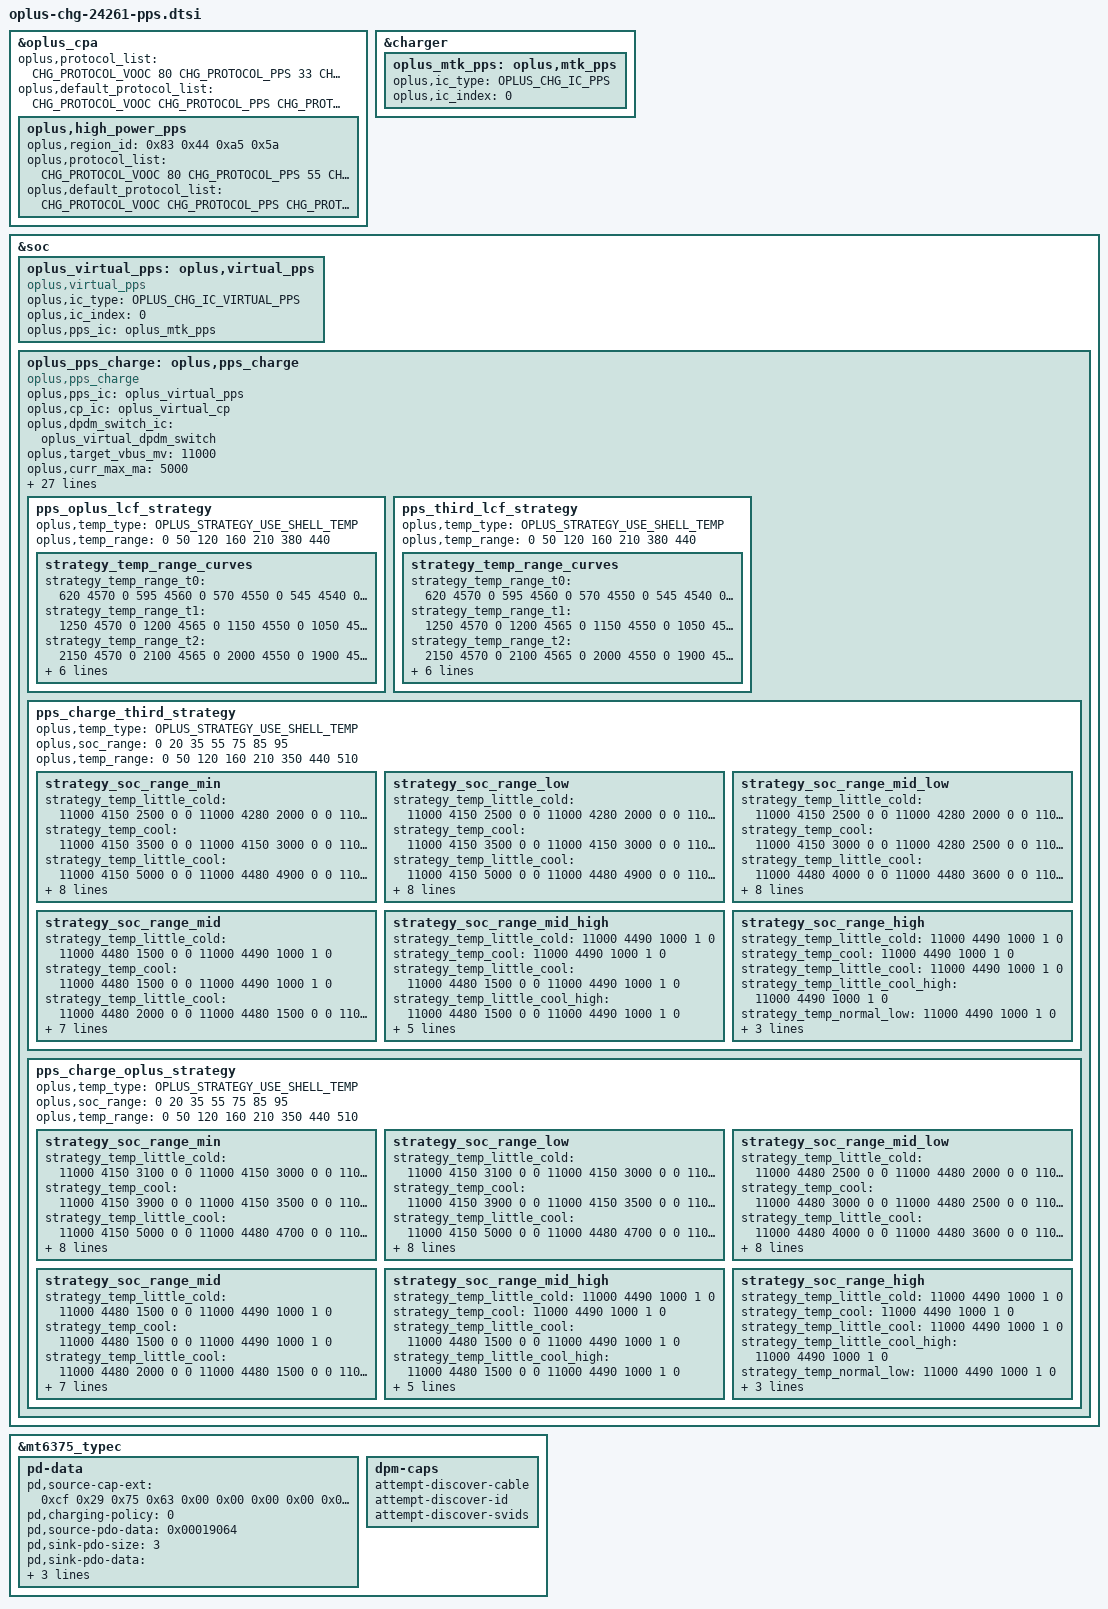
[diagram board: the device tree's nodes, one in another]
//ifdef OPLUS_FEATURE_CHG_BASIC
&oplus_cpa {
	oplus,protocol_list = <CHG_PROTOCOL_VOOC 80
			       CHG_PROTOCOL_PPS 33
			       CHG_PROTOCOL_PD 18
			       CHG_PROTOCOL_QC 18>;
	oplus,default_protocol_list = <CHG_PROTOCOL_VOOC
				       CHG_PROTOCOL_PPS
				       CHG_PROTOCOL_PD>;
	oplus,high_power_pps {
		oplus,region_id = /bits/ 8 <0x83 0x44 0xa5 0x5a>;
		oplus,protocol_list = <CHG_PROTOCOL_VOOC 80
				       CHG_PROTOCOL_PPS 55
				       CHG_PROTOCOL_PD 18
				       CHG_PROTOCOL_QC 18>;
		oplus,default_protocol_list = <CHG_PROTOCOL_VOOC
					       CHG_PROTOCOL_PPS
					       CHG_PROTOCOL_PD>;
	};
};

&charger {
	oplus_mtk_pps: oplus,mtk_pps {
		oplus,ic_type = <OPLUS_CHG_IC_PPS>;
		oplus,ic_index = <0>;
	};
};
&soc {
	oplus_virtual_pps: oplus,virtual_pps {
		compatible = "oplus,virtual_pps";

		oplus,ic_type = <OPLUS_CHG_IC_VIRTUAL_PPS>;
		oplus,ic_index = <0>;
		oplus,pps_ic = <&oplus_mtk_pps>;
	};
	oplus_pps_charge: oplus,pps_charge {
		compatible = "oplus,pps_charge";
		oplus,pps_ic = <&oplus_virtual_pps>;
		oplus,cp_ic = <&oplus_virtual_cp>;
		oplus,dpdm_switch_ic = <&oplus_virtual_dpdm_switch>;

		oplus,target_vbus_mv = <11000>;
		oplus,curr_max_ma = <5000>;

		oplus,pps_warm_allow_vol = <4000>;
		oplus,pps_warm_allow_soc = <50>;
		oplus,pps_strategy_normal_current = <5000>;
		oplus,pps_over_high_or_low_current = <3000>;
		oplus,pps_timeout_third = <10800>;
		oplus,pps_timeout_oplus = <10800>;
		oplus,pps_ibat_over_third = <12000>;
		oplus,pps_ibat_over_oplus = <12000>;
		oplus,pps_full_cool_sw_vbat = <4490>;
		oplus,pps_full_normal_sw_vbat = <4490>;
		oplus,pps_full_normal_hw_vbat = <4500>;
		oplus,pps_full_ffc_vbat = <4500>;
		oplus,pps_full_warm_vbat = <4130>;
		oplus,pps_full_cool_sw_vbat_third = <4490>;
		oplus,pps_full_normal_sw_vbat_third= <4490>;
		oplus,pps_full_normal_hw_vbat_third = <4500>;
		oplus,pps_current_change_timeout = <100>;
		oplus,curve_strategy_name = "pps_ufcs_curve_v2";
		oplus,pps_strategy_batt_high_temp = <410 420 430 400 410 420>;
		oplus,pps_strategy_high_current = <5000 4000 3000 5000 4000 3000>;
		oplus,pps_little_cool_high_temp = <210>;
		oplus,pps_charge_strategy_soc = <0 20 35 55 75 85 95>;
		oplus,pps_charge_strategy_temp = <0 50 120 160 350 440 510>;

		pps_oplus_lcf_strategy {
			oplus,temp_type = <OPLUS_STRATEGY_USE_SHELL_TEMP>;
			oplus,temp_range = <0 50 120 160 210 380 440>;

			strategy_temp_range_curves {
				strategy_temp_range_t0 =	<620 4570 0
								 595 4560 0
								 570 4550 0
								 545 4540 0
								 520 4530 1>;
				strategy_temp_range_t1 =	<1250 4570 0
								 1200 4565 0
								 1150 4550 0
								 1050 4540 0
								 950 4530 1>;
				strategy_temp_range_t2 =	<2150 4570 0
								 2100 4565 0
								 2000 4550 0
								 1900 4540 0
								 1750 4530 1>;
				strategy_temp_range_t3 =	<3400 4570 0
								 3350 4565 0
								 3250 4550 0
								 3150 4540 0
								 3000 4530 1>;
				strategy_temp_range_t4 =	<3400 4570 0
								 3350 4565 0
								 3250 4550 0
								 3150 4540 0
								 3000 4530 1>;
				strategy_temp_range_t5 =	<4300 4570 0
								 4250 4565 0
								 4150 4550 0
								 4050 4540 0
								 3900 4530 1>;
			};
		};

		pps_third_lcf_strategy {
			oplus,temp_type = <OPLUS_STRATEGY_USE_SHELL_TEMP>;
			oplus,temp_range = <0 50 120 160 210 380 440>;

			strategy_temp_range_curves {
				strategy_temp_range_t0 =	<620 4570 0
								 595 4560 0
								 570 4550 0
								 545 4540 0
								 520 4530 1>;
				strategy_temp_range_t1 =	<1250 4570 0
								 1200 4565 0
								 1150 4550 0
								 1050 4540 0
								 950 4530 1>;
				strategy_temp_range_t2 =	<2150 4570 0
								 2100 4565 0
								 2000 4550 0
								 1900 4540 0
								 1750 4530 1>;
				strategy_temp_range_t3 =	<3400 4570 0
								 3350 4565 0
								 3250 4550 0
								 3150 4540 0
								 3000 4530 1>;
				strategy_temp_range_t4 =	<3400 4570 0
								 3350 4565 0
								 3250 4550 0
								 3150 4540 0
								 3000 4530 1>;
				strategy_temp_range_t5 =	<4300 4570 0
								 4250 4565 0
								 4150 4550 0
								 4050 4540 0
								 3900 4530 1>;
			};
		};

		pps_charge_third_strategy {
			oplus,temp_type = <OPLUS_STRATEGY_USE_SHELL_TEMP>;
			oplus,soc_range = <0 20 35 55 75 85 95>;
			oplus,temp_range = <0 50 120 160 210 350 440 510>;

			strategy_soc_range_min {
				strategy_temp_little_cold =	<11000 4150 2500 0 0
								11000 4280 2000 0 0
								11000 4480 1500 0 0
								11000 4490 1000 1 0>;
				strategy_temp_cool =		<11000 4150 3500 0 0
								11000 4150 3000 0 0
								11000 4280 2500 0 0
								11000 4480 2000 0 0
								11000 4480 1500 0 0
								11000 4490 1000 1 0>;
				strategy_temp_little_cool =	<11000 4150 5000 0 0
								11000 4480 4900 0 0
								11000 4480 4000 0 0
								11000 4480 3600 0 0
								11000 4480 3500 0 0
								11000 4480 3000 0 0
								11000 4480 2500 0 0
								11000 4480 2000 0 0
								11000 4480 1500 0 0
								11000 4490 1000 1 0>;
				strategy_temp_little_cool_high =	<11000 4280 5000 0 0
								11000 4480 4900 0 0
								11000 4480 4000 0 0
								11000 4480 3600 0 0
								11000 4480 3500 0 0
								11000 4480 3000 0 0
								11000 4480 2500 0 0
								11000 4480 2000 0 0
								11000 4480 1500 0 0
								11000 4490 1000 1 0>;
				strategy_temp_normal_low =	<11000 4280 5000 0 0
								11000 4480 4900 0 0
								11000 4480 4000 0 0
								11000 4480 3600 0 0
								11000 4480 3500 0 0
								11000 4480 3000 0 0
								11000 4480 2500 0 0
								11000 4480 2000 0 0
								11000 4480 1500 0 0
								11000 4490 1000 1 0>;
				strategy_temp_normal_high =	<11000 4280 5000 0 0
								11000 4460 4900 0 0
								11000 4460 4000 0 0
								11000 4460 3600 0 0
								11000 4460 3500 0 0
								11000 4460 3000 0 0
								11000 4460 2500 0 0
								11000 4460 2000 0 0
								11000 4460 1500 0 0
								11000 4470 1000 1 0>;
				strategy_temp_warm =		<11000 4120 1500 0 0
								11000 4130 1000 1 0>;
			};
			strategy_soc_range_low {
				strategy_temp_little_cold =	<11000 4150 2500 0 0
								11000 4280 2000 0 0
								11000 4480 1500 0 0
								11000 4490 1000 1 0>;
				strategy_temp_cool =		<11000 4150 3500 0 0
								11000 4150 3000 0 0
								11000 4280 2500 0 0
								11000 4480 2000 0 0
								11000 4480 1500 0 0
								11000 4490 1000 1 0>;
				strategy_temp_little_cool =	<11000 4150 5000 0 0
								11000 4480 4900 0 0
								11000 4480 4000 0 0
								11000 4480 3600 0 0
								11000 4480 3500 0 0
								11000 4480 3000 0 0
								11000 4480 2500 0 0
								11000 4480 2000 0 0
								11000 4480 1500 0 0
								11000 4490 1000 1 0>;
				strategy_temp_little_cool_high =	<11000 4280 5000 0 0
								11000 4480 4900 0 0
								11000 4480 4000 0 0
								11000 4480 3600 0 0
								11000 4480 3500 0 0
								11000 4480 3000 0 0
								11000 4480 2500 0 0
								11000 4480 2000 0 0
								11000 4480 1500 0 0
								11000 4490 1000 1 0>;
				strategy_temp_normal_low =	<11000 4280 5000 0 0
								11000 4480 4900 0 0
								11000 4480 4000 0 0
								11000 4480 3600 0 0
								11000 4480 3500 0 0
								11000 4480 3000 0 0
								11000 4480 2500 0 0
								11000 4480 2000 0 0
								11000 4480 1500 0 0
								11000 4490 1000 1 0>;
				strategy_temp_normal_high =	<11000 4280 5000 0 0
								11000 4460 4900 0 0
								11000 4460 4000 0 0
								11000 4460 3600 0 0
								11000 4460 3500 0 0
								11000 4460 3000 0 0
								11000 4460 2500 0 0
								11000 4460 2000 0 0
								11000 4460 1500 0 0
								11000 4470 1000 1 0>;
				strategy_temp_warm =		<11000 4120 1500 0 0
								11000 4130 1000 1 0>;
			};
			strategy_soc_range_mid_low {
				strategy_temp_little_cold =	<11000 4150 2500 0 0
								11000 4280 2000 0 0
								11000 4480 1500 0 0
								11000 4490 1000 1 0>;
				strategy_temp_cool =		<11000 4150 3000 0 0
								11000 4280 2500 0 0
								11000 4480 2000 0 0
								11000 4480 1500 0 0
								11000 4490 1000 1 0>;
				strategy_temp_little_cool =	<11000 4480 4000 0 0
								11000 4480 3600 0 0
								11000 4480 3500 0 0
								11000 4480 3000 0 0
								11000 4480 2500 0 0
								11000 4480 2000 0 0
								11000 4480 1500 0 0
								11000 4490 1000 1 0>;
				strategy_temp_little_cool_high =	<11000 4480 4000 0 0
								11000 4480 3600 0 0
								11000 4480 3500 0 0
								11000 4480 3000 0 0
								11000 4480 2500 0 0
								11000 4480 2000 0 0
								11000 4480 1500 0 0
								11000 4490 1000 1 0>;
				strategy_temp_normal_low =	<11000 4280 5000 0 0
								11000 4480 4900 0 0
								11000 4480 4000 0 0
								11000 4480 3600 0 0
								11000 4480 3500 0 0
								11000 4480 3000 0 0
								11000 4480 2500 0 0
								11000 4480 2000 0 0
								11000 4480 1500 0 0
								11000 4490 1000 1 0>;
				strategy_temp_normal_high =	<11000 4280 5000 0 0
								11000 4460 4900 0 0
								11000 4460 4000 0 0
								11000 4460 3600 0 0
								11000 4460 3500 0 0
								11000 4460 3000 0 0
								11000 4460 2500 0 0
								11000 4460 2000 0 0
								11000 4460 1500 0 0
								11000 4470 1000 1 0>;
				strategy_temp_warm =		<11000 4120 1500 0 0
								11000 4130 1000 1 0>;
			};
			strategy_soc_range_mid {
				strategy_temp_little_cold =	<11000 4480 1500 0 0
								11000 4490 1000 1 0>;
				strategy_temp_cool =		<11000 4480 1500 0 0
								11000 4490 1000 1 0>;
				strategy_temp_little_cool =	<11000 4480 2000 0 0
								11000 4480 1500 0 0
								11000 4490 1000 1 0>;
				strategy_temp_little_cool_high =	<11000 4480 2000 0 0
								11000 4480 1500 0 0
								11000 4490 1000 1 0>;
				strategy_temp_normal_low =	<11000 4480 2500 0 0
								11000 4480 2000 0 0
								11000 4480 1500 0 0
								11000 4490 1000 1 0>;
				strategy_temp_normal_high =	<11000 4460 3000 0 0
								11000 4460 2500 0 0
								11000 4460 2000 0 0
								11000 4460 1500 0 0
								11000 4470 1000 1 0>;
				strategy_temp_warm =		<11000 4130 1000 1 0>;
			};
			strategy_soc_range_mid_high {
				strategy_temp_little_cold =	<11000 4490 1000 1 0>;
				strategy_temp_cool =		<11000 4490 1000 1 0>;
				strategy_temp_little_cool =	<11000 4480 1500 0 0
								11000 4490 1000 1 0>;
				strategy_temp_little_cool_high =	<11000 4480 1500 0 0
								11000 4490 1000 1 0>;
				strategy_temp_normal_low =	<11000 4480 2000 0 0
								11000 4480 1500 0 0
								11000 4490 1000 1 0>;
				strategy_temp_normal_high =	<11000 4460 2500 0 0
								11000 4460 2000 0 0
								11000 4460 1500 0 0
								11000 4470 1000 1 0>;
				strategy_temp_warm =		<11000 4130 1000 1 0>;
			};
			strategy_soc_range_high {
				strategy_temp_little_cold =	<11000 4490 1000 1 0>;
				strategy_temp_cool =		<11000 4490 1000 1 0>;
				strategy_temp_little_cool =	<11000 4490 1000 1 0>;
				strategy_temp_little_cool_high =	<11000 4490 1000 1 0>;
				strategy_temp_normal_low =	<11000 4490 1000 1 0>;
				strategy_temp_normal_high =	<11000 4460 1500 0 0
								11000 4470 1000 1 0>;
				strategy_temp_warm =		<11000 4130 1000 1 0>;
			};
		};


		pps_charge_oplus_strategy {
			oplus,temp_type = <OPLUS_STRATEGY_USE_SHELL_TEMP>;
			oplus,soc_range = <0 20 35 55 75 85 95>;
			oplus,temp_range = <0 50 120 160 210 350 440 510>;

			strategy_soc_range_min {
				strategy_temp_little_cold =	<11000 4150 3100 0 0
								11000 4150 3000 0 0
								11000 4480 2600 0 0
								11000 4480 2500 0 0
								11000 4480 2000 0 0
								11000 4480 1500 0 0
								11000 4490 1000 1 0>;
				strategy_temp_cool =		<11000 4150 3900 0 0
								11000 4150 3500 0 0
								11000 4480 3100 0 0
								11000 4480 3000 0 0
								11000 4480 2500 0 0
								11000 4480 2000 0 0
								11000 4480 1500 0 0
								11000 4490 1000 1 0>;
				strategy_temp_little_cool =	<11000 4150 5000 0 0
								11000 4480 4700 0 0
								11000 4480 4000 0 0
								11000 4480 3600 0 0
								11000 4480 3500 0 0
								11000 4480 3000 0 0
								11000 4480 2500 0 0
								11000 4480 2000 0 0
								11000 4480 1500 0 0
								11000 4490 1000 1 0>;
				strategy_temp_little_cool_high =	<11000 4280 5000 0 0
								11000 4480 4900 0 0
								11000 4480 4000 0 0
								11000 4480 3600 0 0
								11000 4480 3500 0 0
								11000 4480 3000 0 0
								11000 4480 2500 0 0
								11000 4480 2000 0 0
								11000 4480 1500 0 0
								11000 4490 1000 1 0>;
				strategy_temp_normal_low =	<11000 4280 5000 0 0
								11000 4480 4900 0 0
								11000 4480 4000 0 0
								11000 4480 3600 0 0
								11000 4480 3500 0 0
								11000 4480 3000 0 0
								11000 4480 2500 0 0
								11000 4480 2000 0 0
								11000 4480 1500 0 0
								11000 4490 1000 1 0>;
				strategy_temp_normal_high =	<11000 4280 5000 0 0
								11000 4460 4900 0 0
								11000 4460 4000 0 0
								11000 4460 3600 0 0
								11000 4460 3500 0 0
								11000 4460 3000 0 0
								11000 4460 2500 0 0
								11000 4460 2000 0 0
								11000 4460 1500 0 0
								11000 4470 1000 1 0>;
				strategy_temp_warm =		<11000 4120 1500 0 0
								11000 4130 1000 1 0>;
			};
			strategy_soc_range_low {
				strategy_temp_little_cold =	<11000 4150 3100 0 0
								11000 4150 3000 0 0
								11000 4480 2600 0 0
								11000 4480 2500 0 0
								11000 4480 2000 0 0
								11000 4480 1500 0 0
								11000 4490 1000 1 0>;
				strategy_temp_cool =		<11000 4150 3900 0 0
								11000 4150 3500 0 0
								11000 4480 3100 0 0
								11000 4480 3000 0 0
								11000 4480 2500 0 0
								11000 4480 2000 0 0
								11000 4480 1500 0 0
								11000 4490 1000 1 0>;
				strategy_temp_little_cool =	<11000 4150 5000 0 0
								11000 4480 4700 0 0
								11000 4480 4000 0 0
								11000 4480 3600 0 0
								11000 4480 3500 0 0
								11000 4480 3000 0 0
								11000 4480 2500 0 0
								11000 4480 2000 0 0
								11000 4480 1500 0 0
								11000 4490 1000 1 0>;
				strategy_temp_little_cool_high =	<11000 4280 5000 0 0
								11000 4480 4900 0 0
								11000 4480 4000 0 0
								11000 4480 3600 0 0
								11000 4480 3500 0 0
								11000 4480 3000 0 0
								11000 4480 2500 0 0
								11000 4480 2000 0 0
								11000 4480 1500 0 0
								11000 4490 1000 1 0>;
				strategy_temp_normal_low =	<11000 4280 5000 0 0
								11000 4480 4900 0 0
								11000 4480 4000 0 0
								11000 4480 3600 0 0
								11000 4480 3500 0 0
								11000 4480 3000 0 0
								11000 4480 2500 0 0
								11000 4480 2000 0 0
								11000 4480 1500 0 0
								11000 4490 1000 1 0>;
				strategy_temp_normal_high =	<11000 4280 5000 0 0
								11000 4460 4900 0 0
								11000 4460 4000 0 0
								11000 4460 3600 0 0
								11000 4460 3500 0 0
								11000 4460 3000 0 0
								11000 4460 2500 0 0
								11000 4460 2000 0 0
								11000 4460 1500 0 0
								11000 4470 1000 1 0>;
				strategy_temp_warm =		<11000 4120 1500 0 0
								11000 4130 1000 1 0>;
			};
			strategy_soc_range_mid_low {
				strategy_temp_little_cold =	<11000 4480 2500 0 0
								11000 4480 2000 0 0
								11000 4480 1500 0 0
								11000 4490 1000 1 0>;
				strategy_temp_cool =		<11000 4480 3000 0 0
								11000 4480 2500 0 0
								11000 4480 2000 0 0
								11000 4480 1500 0 0
								11000 4490 1000 1 0>;
				strategy_temp_little_cool =	<11000 4480 4000 0 0
								11000 4480 3600 0 0
								11000 4480 3500 0 0
								11000 4480 3000 0 0
								11000 4480 2500 0 0
								11000 4480 2000 0 0
								11000 4480 1500 0 0
								11000 4490 1000 1 0>;
				strategy_temp_little_cool_high =	<11000 4480 4000 0 0
								11000 4480 3600 0 0
								11000 4480 3500 0 0
								11000 4480 3000 0 0
								11000 4480 2500 0 0
								11000 4480 2000 0 0
								11000 4480 1500 0 0
								11000 4490 1000 1 0>;
				strategy_temp_normal_low =	<11000 4280 5000 0 0
								11000 4480 4900 0 0
								11000 4480 4000 0 0
								11000 4480 3600 0 0
								11000 4480 3500 0 0
								11000 4480 3000 0 0
								11000 4480 2500 0 0
								11000 4480 2000 0 0
								11000 4480 1500 0 0
								11000 4490 1000 1 0>;
				strategy_temp_normal_high =	<11000 4280 5000 0 0
								11000 4460 4900 0 0
								11000 4460 4000 0 0
								11000 4460 3600 0 0
								11000 4460 3500 0 0
								11000 4460 3000 0 0
								11000 4460 2500 0 0
								11000 4460 2000 0 0
								11000 4460 1500 0 0
								11000 4470 1000 1 0>;
				strategy_temp_warm =		<11000 4120 1500 0 0
								11000 4130 1000 1 0>;
			};
			strategy_soc_range_mid {
				strategy_temp_little_cold =	<11000 4480 1500 0 0
								11000 4490 1000 1 0>;
				strategy_temp_cool =		<11000 4480 1500 0 0
								11000 4490 1000 1 0>;
				strategy_temp_little_cool =	<11000 4480 2000 0 0
								11000 4480 1500 0 0
								11000 4490 1000 1 0>;
				strategy_temp_little_cool_high =	<11000 4480 2000 0 0
								11000 4480 1500 0 0
								11000 4490 1000 1 0>;
				strategy_temp_normal_low =	<11000 4480 2500 0 0
								11000 4480 2000 0 0
								11000 4480 1500 0 0
								11000 4490 1000 1 0>;
				strategy_temp_normal_high =	<11000 4460 3000 0 0
								11000 4460 2500 0 0
								11000 4460 2000 0 0
								11000 4460 1500 0 0
								11000 4470 1000 1 0>;
				strategy_temp_warm =		<11000 4130 1000 1 0>;
			};
			strategy_soc_range_mid_high {
				strategy_temp_little_cold =	<11000 4490 1000 1 0>;
				strategy_temp_cool =		<11000 4490 1000 1 0>;
				strategy_temp_little_cool =	<11000 4480 1500 0 0
								11000 4490 1000 1 0>;
				strategy_temp_little_cool_high =	<11000 4480 1500 0 0
								11000 4490 1000 1 0>;
				strategy_temp_normal_low =	<11000 4480 2000 0 0
								11000 4480 1500 0 0
								11000 4490 1000 1 0>;
				strategy_temp_normal_high =	<11000 4460 2500 0 0
								11000 4460 2000 0 0
								11000 4460 1500 0 0
								11000 4470 1000 1 0>;
				strategy_temp_warm =		<11000 4130 1000 1 0>;
			};
			strategy_soc_range_high {
				strategy_temp_little_cold =	<11000 4490 1000 1 0>;
				strategy_temp_cool =		<11000 4490 1000 1 0>;
				strategy_temp_little_cool =	<11000 4490 1000 1 0>;
				strategy_temp_little_cool_high =	<11000 4490 1000 1 0>;
				strategy_temp_normal_low =	<11000 4490 1000 1 0>;
				strategy_temp_normal_high =	<11000 4460 1500 0 0
								11000 4470 1000 1 0>;
				strategy_temp_warm =		<11000 4130 1000 1 0>;
			};
		};
	};
};

/* for pd common charger */
&mt6375_typec {
	pd-data {
			pd,source-cap-ext = /bits/ 8 <0xcf 0x29 0x75 0x63
							      0x00 0x00 0x00 0x00
							      0x00 0x00 0x00 0x00
							      0x00 0x00 0x00 0x00
							      0x00 0x00 0x00 0x00
							      0x00 0x00 0x01 0x05
							      0x00>;

			pd,charging-policy = <0>;

			pd,source-pdo-data = <0x00019064>;/* Fixed, 5000mV, 1000mA*/

			/*0x000190c8: Fixed, 5000mV, 2000mA*/
			/*0x0002d096: Fixed, 9000mV, 1500mA*/
			/*0xc0dc1e64: apdo, min 3000mV, max 11000mV, 5000mA*/
			pd,sink-pdo-size = <3>;
			pd,sink-pdo-data = <0x000190c8 0x0002d096 0xc0dc1e64>;

			/* No DP, host + device */
			pd,id-vdo-data = <0xd14029cf 0x0 0x63750000
						  0x61000000 0x0 0x41000000>;
	};

	dpm-caps {
			// attempt-enter-dp-mode;
			attempt-discover-cable;
			attempt-discover-id;
			attempt-discover-svids;
	};
};

//#endif OPLUS_FEATURE_CHG_BASIC
